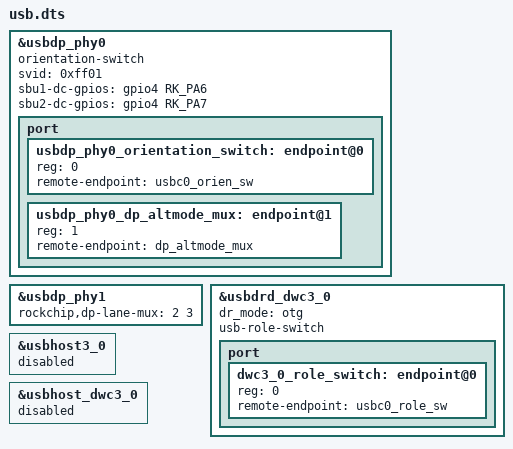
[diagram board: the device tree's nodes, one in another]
&usbdp_phy0 {
	orientation-switch;
	svid = <0xff01>;
	sbu1-dc-gpios = <&gpio4 RK_PA6 GPIO_ACTIVE_HIGH>;
	sbu2-dc-gpios = <&gpio4 RK_PA7 GPIO_ACTIVE_HIGH>;

	port {
		#address-cells = <1>;
		#size-cells = <0>;
		usbdp_phy0_orientation_switch: endpoint@0 {
			reg = <0>;
			remote-endpoint = <&usbc0_orien_sw>;
		};

		usbdp_phy0_dp_altmode_mux: endpoint@1 {
			reg = <1>;
			remote-endpoint = <&dp_altmode_mux>;
		};
	};
};

&usbdp_phy1 {
	rockchip,dp-lane-mux = <2 3>;
};

&usbdrd_dwc3_0 {
	dr_mode = "otg";
	usb-role-switch;
	port {
		#address-cells = <1>;
		#size-cells = <0>;
		dwc3_0_role_switch: endpoint@0 {
			reg = <0>;
			remote-endpoint = <&usbc0_role_sw>;
		};
	};
};

&usbhost3_0 {
	status = "disabled";
};

&usbhost_dwc3_0 {
	status = "disabled";
};
